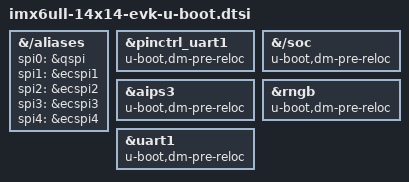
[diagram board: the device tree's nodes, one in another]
// SPDX-License-Identifier: GPL-2.0+
/*
 * Copyright 2022-2023 NXP
 * Copyright 2020 Foundries.io
 */

&{/aliases} {
	spi0 = &qspi;
	spi1 = &ecspi1;
	spi2 = &ecspi2;
	spi3 = &ecspi3;
	spi4 = &ecspi4;
};

&pinctrl_uart1 {
	u-boot,dm-pre-reloc;
	u-boot,dm-spl;
};

&{/soc} {
	u-boot,dm-pre-reloc;
	u-boot,dm-spl;
};

&aips3 {
	u-boot,dm-pre-reloc;
	u-boot,dm-spl;
};

&rngb {
	u-boot,dm-pre-reloc;
	u-boot,dm-spl;
};

&uart1 {
	u-boot,dm-pre-reloc;
	u-boot,dm-spl;
};
